# STM32G4xx register map
File version: 1.4
CPU: CM4 r0p1, little endian, MPU, FPU, 4 interrupt priority bits
Registers are 32-bit, read-write, reset 0x0 unless marked. A register's access mark holds for its fields unless they carry their own. Offsets are from the block's base; [hi:lo] are bit positions; {n}, {i} and the like mark numbered series; 'fields as' and 'values as' point back to an identical list.

## DMA1 — DMA controller
Base 0x40020000
Same registers: DMA2 0x40020400
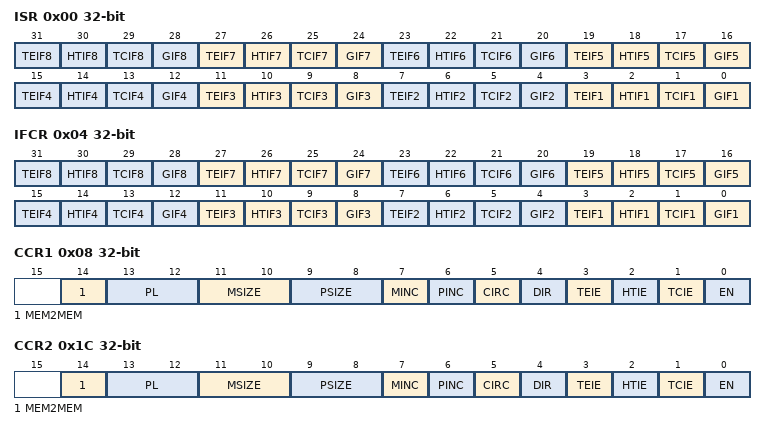
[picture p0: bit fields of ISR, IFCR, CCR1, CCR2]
0x00 ISR ro — interrupt status register
  [4n-1] TEIF{n} (n=1..8), [4n-2] HTIF{n} (n=1..8), [4n-3] TCIF{n} (n=1..8), [4n-4] GIF{n} (n=1..8)
0x04 IFCR ro — DMA interrupt flag clear register
  fields as ISR
0x08 CCR1 — DMA channel 1 configuration register
  [14] MEM2MEM
  [13:12] PL
  [11:10] MSIZE
  [9:8] PSIZE
  [7] MINC
  [6] PINC
  [5] CIRC
  [4] DIR
  [3] TEIE
  [2] HTIE
  [1] TCIE
  [0] EN — channel enable
0x0C CNDTR1 — channel x number of data to transfer register
  [15:0] NDT — Number of data items to transfer
0x10 CPAR1 — DMA channel x peripheral address register
  [31:0] PA — Peripheral address
{0x0+0x14*i} CMAR{i} (i=1..8) — DMA channel x memory address register
  [31:0] MA — Memory 1 address (used in case of Double buffer mode)
0x1C CCR2 — DMA channel 2 configuration register
  fields as CCR1
0x20 CNDTR2 — channel x number of data to transfer register
  [15:0] NDT — Number of data items to transfer
0x24 CPAR2 — DMA channel x peripheral address register
  [31:0] PA — Peripheral address
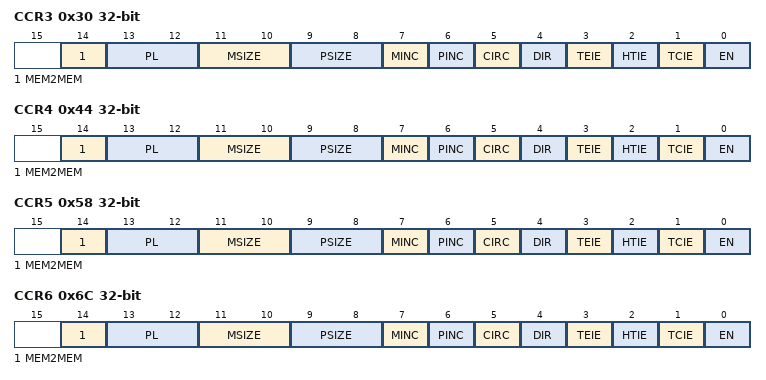
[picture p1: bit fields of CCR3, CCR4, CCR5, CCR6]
0x30 CCR3 — DMA channel 3 configuration register
  fields as CCR1
0x34 CNDTR3 — channel x number of data to transfer register
  [15:0] NDT — Number of data items to transfer
0x38 CPAR3 — DMA channel x peripheral address register
  [31:0] PA — Peripheral address
0x44 CCR4 — DMA channel 3 configuration register
  fields as CCR1
0x48 CNDTR4 — channel x number of data to transfer register
  [15:0] NDT — Number of data items to transfer
0x4C CPAR4 — DMA channel x peripheral address register
  [31:0] PA — Peripheral address
0x58 CCR5 — DMA channel 4 configuration register
  fields as CCR1
0x5C CNDTR5 — channel x number of data to transfer register
  [15:0] NDT — Number of data items to transfer
0x60 CPAR5 — DMA channel x peripheral address register
  [31:0] PA — Peripheral address
0x6C CCR6 — DMA channel 5 configuration register
  fields as CCR1
0x70 CNDTR6 — channel x number of data to transfer register
  [15:0] NDT — Number of data items to transfer
0x74 CPAR6 — DMA channel x peripheral address register
  [31:0] PA — Peripheral address
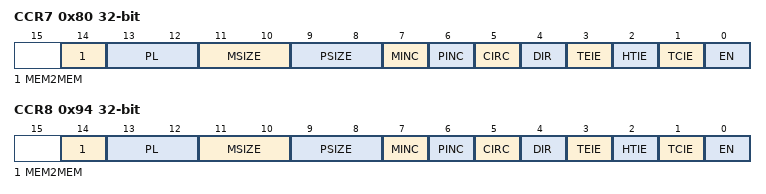
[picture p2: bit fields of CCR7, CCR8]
0x80 CCR7 — DMA channel 6 configuration register
  fields as CCR1
0x84 CNDTR7 — channel x number of data to transfer register
  [15:0] NDT — Number of data items to transfer
0x88 CPAR7 — DMA channel x peripheral address register
  [31:0] PA — Peripheral address
0x94 CCR8 — DMA channel 7 configuration register
  fields as CCR1
0x98 CNDTR8 — channel x number of data to transfer register
  [15:0] NDT — Number of data items to transfer
0x9C CPAR8 — DMA channel x peripheral address register
  [31:0] PA — Peripheral address

## DMAMUX
Base 0x40020800
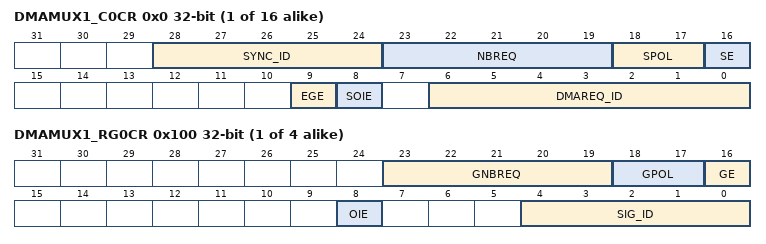
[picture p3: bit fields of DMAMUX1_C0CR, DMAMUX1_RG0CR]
{0x0+4i} DMAMUX1_C{i}CR (i=0..15) — DMAMux - DMA request line multiplexer channel x control register
  [28:24] SYNC_ID — Synchronization input selected
  [23:19] NBREQ — Number of DMA requests to forward Defines the number of DMA requests forwarded before output event is generated. In synchronous mode, it also defines the number of DMA requests to forward after a synchronization event, then stop forwarding. The actual number of DMA requests forwarded is NBREQ+1. Note: This field can only be written when both SE and EGE bits are reset.
  [18:17] SPOL — Synchronization event type selector Defines the synchronization event on the selected synchronization input:
  [16] SE — Synchronous operating mode enable/disable
  [9] EGE — Event generation enable/disable
  [8] SOIE — Interrupt enable at synchronization event overrun
  [6:0] DMAREQ_ID — Input DMA request line selected
0x80 DMAMUX1_CSR ro — DMAMUX request line multiplexer interrupt channel status register
  [15:0] SOF — Synchronization overrun event flag
0x84 DMAMUX1_CFR wo — DMAMUX request line multiplexer interrupt clear flag register
  [15:0] CSOF — Clear synchronization overrun event flag
{0x100+4i} DMAMUX1_RG{i}CR (i=0..3) — DMAMux - DMA request generator channel x control register
  [23:19] GNBREQ — Number of DMA requests to generate Defines the number of DMA requests generated after a trigger event, then stop generating. The actual number of generated DMA requests is GNBREQ+1. Note: This field can only be written when GE bit is reset.
  [18:17] GPOL — DMA request generator trigger event type selection Defines the trigger event on the selected DMA request trigger input
  [16] GE — DMA request generator channel enable/disable
  [8] OIE — Interrupt enable at trigger event overrun
  [4:0] SIG_ID — DMA request trigger input selected
0x140 DMAMUX1_RGSR ro — DMAMux - DMA request generator status register
  [3:0] OF — Trigger event overrun flag The flag is set when a trigger event occurs on DMA request generator channel x, while the DMA request generator counter value is lower than GNBREQ. The flag is cleared by writing 1 to the corresponding COFx bit in DMAMUX_RGCFR register.
0x144 DMAMUX1_RGCFR wo — DMAMux - DMA request generator clear flag register
  [3:0] COF — Clear trigger event overrun flag Upon setting, this bit clears the corresponding overrun flag OFx in the DMAMUX_RGCSR register.
